# tviic2d6m register map
Vendor: Infineon Technologies; Series: TVIIC2D6M; File version: 1.0
CPU: CM7 r0p1, little endian, MPU, FPU, double-precision FPU, I-cache, D-cache, VTOR, ITCM, DTCM, 3 interrupt priority bits, 16 interrupts
Registers are 32-bit, read-write, reset 0x0 unless marked. A register's access mark holds for its fields unless they carry their own. Offsets are from the block's base; [hi:lo] are bit positions; lines under a group give offsets from that group; {n}, {i} and the like mark numbered series; <NAME> marks a mode.

## PWM0 — PWM
Base 0x40830000
0x00 CTL — Control
  [7:0] ACTIVE — Activate functionality (1 bit for each channel): '0': Transmitter off. The FIFO_UNDERFLOW interrupt cause will not be activated. '1': Transmitter on. The FIFO_UNDERFLOW interrupt may be activated (when an underflow event occurs). Note: Setting this bit is intended for startup purposes. Note: Clearing this bit is intended to return the data lines at '0' prior to disabling the interface.
0x04 CTL_CLR — Control clear
  [7:0] ACTIVE write-1-clears — Activate functionality: '0': No effect. '1': Bit is cleared to '0'.
0x08 CTL_SET — Control set
  [7:0] ACTIVE write-1-sets — Activate functionality: '0': No effect. '1': Bit is set to '1'.
{0x8000+0x100*i} TX[{i}] (i=0..1) group — PWM structure
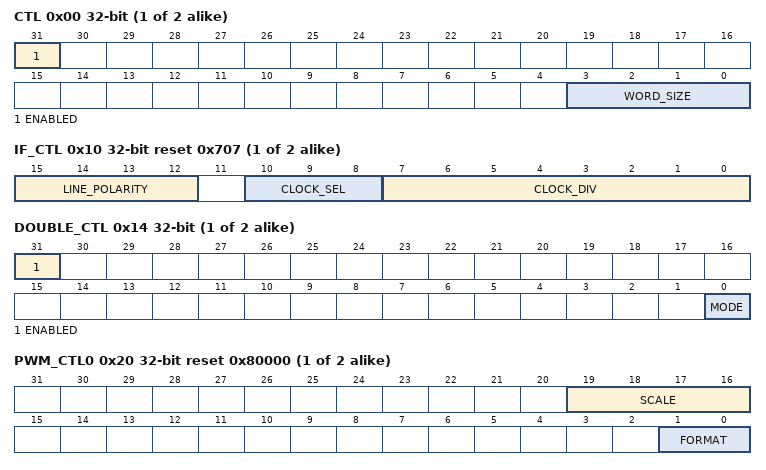
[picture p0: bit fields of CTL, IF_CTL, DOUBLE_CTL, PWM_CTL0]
  0x00 CTL — Control
    [31] ENABLED — Transmitter enable: '0': Disabled. All non-retained MMIO registers (e.g. the TX_FIFO_STATUS and INTR_TX registers) have their fields reset to their default value. The line output signals have a default value of '0' (before applying LINE_POLARITY). '1': Enabled. Note: when all transmitters are disabled, the SRAMs are driven into low power mode, if supported by the SRAM. When exiting such low power mode software needs to allow for a certain power up time before SRAM can be used, i.e. before ACTIVE can be asserted. The power up time is equivalent to the system SRAM power up time specified in the CPUSS.RAM_PWR_DELAY_CTL register (or equivalent for platforms other than MXS40). Note: To return the data lines at '0' prior to disable the interface software can clear the ACTIVE bit prior to clearing the ENABLED field.
    [3:0] WORD_SIZE — PCM word size: '0': 8 bit. '1': 10 bit. '2': 12 bit. '3': 14 bit. '4': 16 bit. '5': 18 bit. '6': 20 bit. '7': 24 bit. '8': 32 bit. '9'-'15': Undefined.
      0=SIZE_8 (N/A); 1=SIZE_10 (N/A); 2=SIZE_12 (N/A); 3=SIZE_14 (N/A); 4=SIZE_16 (N/A); 5=SIZE_18 (N/A); 6=SIZE_20 (N/A); 7=SIZE_24 (N/A); 8=SIZE_32 (N/A)
  0x10 IF_CTL reset 0x707 — Interface control
    [15:12] LINE_POLARITY — Line polarity (one bit for each PWM output signal): '0': Line output signal is used 'as is'. '1': Line output signal inverted. LINE_POLARITY[0]: 'line1_p_out' output signal. LINE_POLARITY[1]: 'line1_n_out' output signal. LINE_POLARITY[2]: 'line2_p_out' output signal. LINE_POLARITY[3]: 'line2_n_out' output signal. Note: the 'line2_p_out'/'line2_n_out' output signals are not used in 'E bridge' format.
    [10:8] CLOCK_SEL — Interface clock clk_if selection: '0': SRSS clock clk_if_srss[0]. '1': SRSS clock clk_if_srss[1]. '2': SRSS clock clk_if_srss[2]. '3': SRSS clock clk_if_srss[3]. '4': Master interface clock 'pwm_mck_in'. '5'-'7': undefined. Note: the application is always required to program this field to a value different from the default.
      {v}=SEL_SRSS_CLOCK{v} (N/A) (v=0..3); 4=SEL_PWM_MCK_IN (N/A)
    [7:0] CLOCK_DIV — Interface clock divider (legal range [0, 255]). The PWM interface clock clk_pwm is defined as clk_if / (CLOCK_DIV + 1). '0': clk_pwm frequency is clk_if frequency (1 clk_pwm cycle consists of 1 clk_if cycles). '1': clk_pwm frequency is 1/2 clk_if frequency (1 clk_pwm cycle consists of 2 clk_if cycles). '2': clk_pwm frequency is 1/3 clk_if frequency. ... '255': clk_pwm frequency is 1/256 clk_if frequency.
  0x14 DOUBLE_CTL — Double control
    [31] ENABLED — Doubler enable: '0': Disabled. doubler_pcm[23:0] = pcm_data[23:0]. '1': Enabled. An 'intermediate' sample is generated through either repetition or averaging (as specified by MODE). This effectively doubles the sample frequency Fs and effectively halves the dynamic PWM sample range (at the same PWM interface clock frequency).
    [0] MODE — Doubler mode (only applicable when ENABLED is '1'): '0': Repetition. An additional sample is created by repeating each TX FIFO data sample. '1': Averaging. An additional sample is calculated by averaging two consecutive TX FIFO data samples.
      0=REPETITION (N/A); 1=AVERAGING (N/A)
  0x18 GAIN_CTL reset 0x73 — Gain control
    [6:0] CODE — Gain code in the range [0, 127]. Each gain code increment represents 1 dB. Gain code value '0' represents digital mute. Gain code '127' represents a maximum amplification of 12 dB. The gain code is used to derive a multipler value (in the range [0, 8191]) and shift value (in the range [11, 26]). '0': digital mute. Multiplier value is '0' and 'shift' is '26'. '1': -114 dB. Multiplier value is '134' and 'shift' is '26'. '2': -113 dB. Multiplier value is '150' and 'shift' is '26'. '3': -112 dB. Multiplier value is '169' and 'shift' is '26'. ... '115': 0 dB. Multiplier value is '4096' and 'shift' is '12'. ... '121': 6 dB. Multiplier value is '8173' and 'shift' is '12'. ... '127': 12 dB. Multiplier value is '8153' and 'shift' is '11'. gc_pcm[15:0] = CLIP16 ((multiplier[12:0]*doubler_pcm[23:0] + (1 << (SCALE - 1)) >> SCALE, with: SCALE = shift + PWM_CTL0.SCALE[3:0]. Note that gain control includes scaling as specified by PWM_CTL0.SCALE[3:0].
  0x20 PWM_CTL0 reset 0x80000 — PWM control 0
    [19:16] SCALE — Scaling of gain corrected PCM sample. See GAIN_CTL.CODE (scaling is performed as part of gain correction).
      0=N/A; 1=N/A; 15=N/A
    [1:0] FORMAT — PWM format: '0': 'E-bridge' format. pcm[16:0] = gc_pcm[15:0] + PWM_CTL2.OFFSET. Output signals 'line1_p_out'/'line1_n_out' are used. '1': 'H-bridge' format. pcm[16:0] = Abs (gc_pcm[15:0]) and sign = gc_pcm[15] (PWM_CTL2.OFFSET is not used). Output signals 'line1_p_out'/'line1_n_out' (when sign is positive/'0') and 'line2_p_out'/'line2_n_out' (when sign is negative/'1') are used. '2': Undefined. '3': Undefined.
      0=E_BRIDGE (N/A); 1=H_BRIDGE (N/A)
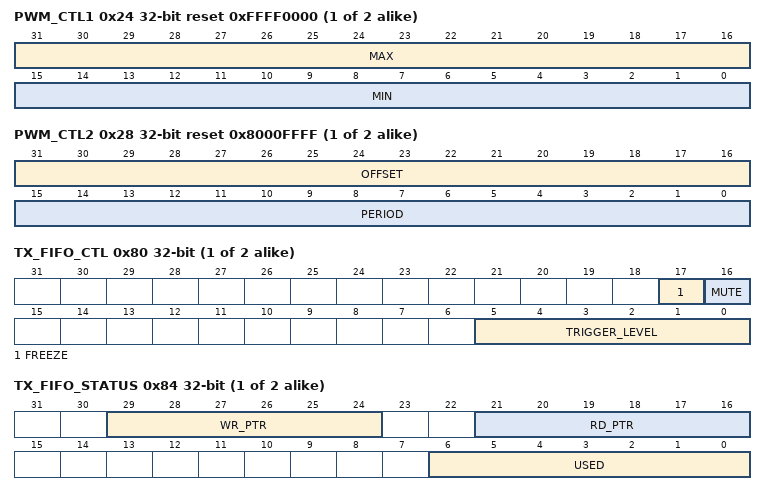
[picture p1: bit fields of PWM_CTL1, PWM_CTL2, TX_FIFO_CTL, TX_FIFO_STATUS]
  0x24 PWM_CTL1 reset 0xFFFF0000 — PWM control 1
    [31:16] MAX — Maximum PWM clip value in the range [0, 65535]. pwm[15:0] = (pcm[16:0] > MAX) ? MAX : (pcm[16:0] < MIN) ? MIN : pcm[15:0] Note: The MIN and MAX values are typically in the range [0, PWM_CTL2.PERIOD].
    [15:0] MIN — Minimum PWM clip value in the range [0, 65535]. Note: This field is typically not used for the H-bridge format (field value should be set to '0').
  0x28 PWM_CTL2 reset 0x8000FFFF — PWM control 2
    [31:16] OFFSET — Offset in the range [0, 0xffff]. Note: This field is only used in 'E-bridge' format. Typically, the offset is half of the PWM period: OFFSET = (PERIOD +1) >> 1.
    [15:0] PERIOD — Period in PWM interface clock cycles (minus 1).
  0x2C PWM_CTL3 — PWM control 3
    [15:0] DT — Dead time in PWM interface clock cycles. Dead time is implemented by 'delaying' the rising edge of all PWM output signals (before applying LINE_POLARITY). Dead time is used to prevent 'shoot through' (direct connection between power supply and ground).
  0x80 TX_FIFO_CTL — TX FIFO control
    [17] FREEZE — Freeze functionality: '0': HW reads from the TX FIFO and advances the FIFO read pointer. '1': HW repeats the previous TX FIFO sample. Freeze does NOT advance the FIFO read pointer. Note: This functionality is intended for debugging purposes. Note: This functionality can also be controlled by the 'tr_dbg_freeze' input signal.
    [16] MUTE — Mute functionality: '0': HW uses TX FIFO data. '1': HW uses a constant PCM data value of '0'. Mute does advance the FIFO read pointer.
    [5:0] TRIGGER_LEVEL — Trigger level. When the TX FIFO has less entries than the number of this field, a transmitter trigger event is generated: - INTR_TX.FIFO_TRIGGER = (# FIFO entries < TRIGGER_LEVEL)
      0=EMPTY (N/A); 1=USED_1 (N/A); 63=USED_63 (N/A)
  0x84 TX_FIFO_STATUS ro
    [29:24] WR_PTR — TX FIFO write pointer: FIFO location at which a new data is written by the hardware. Note: This functionality is intended for debugging purposes.
    [21:16] RD_PTR — TX FIFO read pointer: FIFO location from which a data is read. Note: This functionality is intended for debugging purposes.
    [6:0] USED — Number of used/occupied entries in the TX FIFO. The field value is in the range [0, 64]. When '0', the FIFO is empty. When '64', the FIFO is full.
  0x88 TX_FIFO_WR wo — TX FIFO write
    [31:0] DATA — Data (PCM sample) written to the TX FIFO. Writing adds the data to the TX FIFO; i.e. behavior is similar to that of a PUSH operation (TX_FIFO_STATUS.WR_PTR is incremented and TX_FIFO_STATUS.USED is incremented). The write data (DATA) should be right aligned when it is written to the FIFO entry (data[23:0]): - 8 bit, pcm_data[23:0] = DATA[7:0] << 16. - 10 bit, pcm_data[23:0] = DATA[9:0] << 14. - 12 bit, pcm_data[23:0] = DATA[11:0] << 12. - 14 bit, pcm_data[23:0] = DATA[13:0] << 10. - 16 bit, pcm_data[23:0] = DATA[15:0] << 8. - 18 bit, pcm_data[23:0] = DATA[17:0] << 6. - 20 bit, pcm_data[23:0] = DATA[19:0] << 4. - 24 bit, pcm_data[23:0] = DATA[23:0]. - 32 bit, pcm_data[23:0] = DATA[31:8]. Note: Writing to a full TX FIFO activates INTR.TX_FIFO_OVERFLOW.
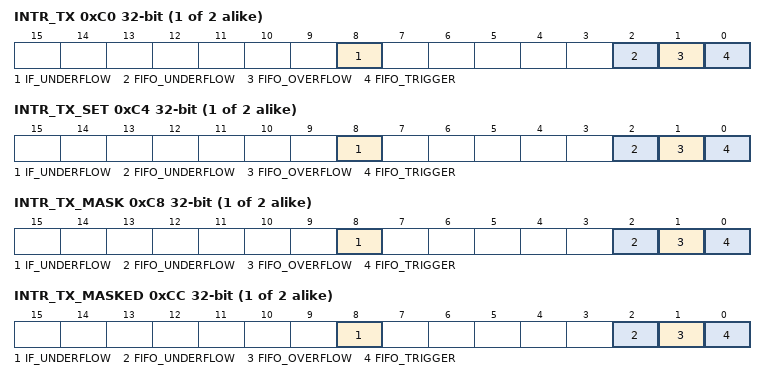
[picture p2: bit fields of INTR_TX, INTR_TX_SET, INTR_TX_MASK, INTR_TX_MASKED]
  0xC0 INTR_TX — Interrupt
    [8] IF_UNDERFLOW write-1-clears — HW sets this field to '1', when PWM samples are not generated in time for the interface logic (interface underflow). This may be an indication that the IP system frequency is too low wrt. the interface frequency (a SW configuration error). The interface underflow is a non-recoverable error and requires SW disabling of the channel (a SW write to INTR_TX.IF_UNDERFLOW does not resolve the interface underflow). The interface drives the 'line1_p' and 'line2_p' output signals to '0' and drives the 'line1_n' and 'line2_n' output signals to '0' also. Note: This functionality is intended for debug purposes.
    [2] FIFO_UNDERFLOW write-1-clears — HW sets this field to '1', when reading from an empty TX FIFO (TX_FIFO_STATUS.USED is '0'). Note: in case of a TX FIFO underflow event, the logic 'replays' the previous PCM value.
    [1] FIFO_OVERFLOW write-1-clears — HW sets this field to '1', when writing to a full TX FIFO (TX_FIFO_STATUS.USED is '64'). This is referred to as an underflow event.
    [0] FIFO_TRIGGER write-1-clears — HW sets this field to '1', when a TX trigger is generated.
  0xC4 INTR_TX_SET — Interrupt set
    [8] IF_UNDERFLOW write-1-sets — Write this field with '1' to set corresponding INTR_TX field (a write of '0' has no effect).
    [2] FIFO_UNDERFLOW write-1-sets — Write this field with '1' to set corresponding INTR_TX field (a write of '0' has no effect).
    [1] FIFO_OVERFLOW write-1-sets — Write this field with '1' to set corresponding INTR_TX field (a write of '0' has no effect).
    [0] FIFO_TRIGGER write-1-sets — Write this field with '1' to set corresponding INTR_TX field (a write of '0' has no effect).
  0xC8 INTR_TX_MASK — Interrupt mask
    [8] IF_UNDERFLOW — Mask for corresponding field in INTR_TX register.
    [2] FIFO_UNDERFLOW — Mask for corresponding field in INTR_TX register.
    [1] FIFO_OVERFLOW — Mask for corresponding field in INTR_TX register.
    [0] FIFO_TRIGGER — Mask for corresponding field in INTR_TX register.
  0xCC INTR_TX_MASKED ro — Interrupt masked
    [8] IF_UNDERFLOW — Logical AND of corresponding INTR_TX and INTR_TX_MASK fields.
    [2] FIFO_UNDERFLOW — Logical AND of corresponding INTR_TX and INTR_TX_MASK fields.
    [1] FIFO_OVERFLOW — Logical AND of corresponding INTR_TX and INTR_TX_MASK fields.
    [0] FIFO_TRIGGER — Logical AND of corresponding INTR_TX and INTR_TX_MASK fields.
